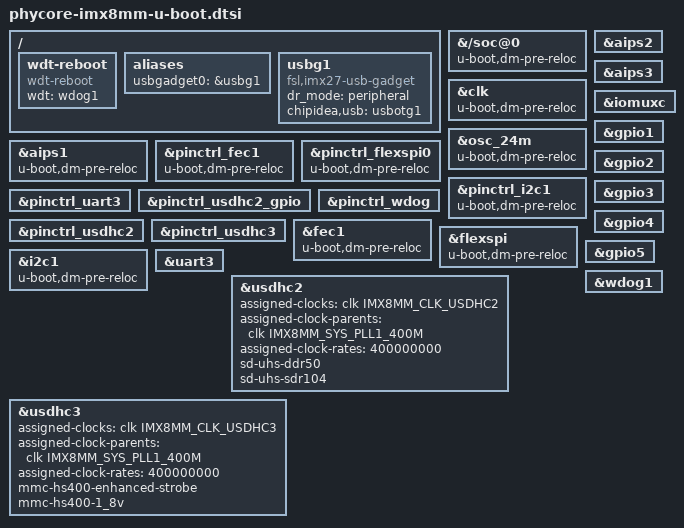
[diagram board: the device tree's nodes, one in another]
// SPDX-License-Identifier: GPL-2.0-or-later
/*
 * Copyright (C) 2020 PHYTEC Messtechnik GmbH
 * Author: Teresa Remmet <t.remmet@phytec.de>
 */

/ {
	wdt-reboot {
		compatible = "wdt-reboot";
		wdt = <&wdog1>;
		u-boot,dm-spl;
	};

	aliases {
		usbgadget0 = &usbg1;
	};

	usbg1: usbg1 {
		compatible = "fsl,imx27-usb-gadget";
		dr_mode = "peripheral";
		chipidea,usb = <&usbotg1>;
		status = "okay";
	};
};

&{/soc@0} {
	u-boot,dm-pre-reloc;
	u-boot,dm-spl;
};

&clk {
	u-boot,dm-spl;
	u-boot,dm-pre-reloc;
	/delete-property/ assigned-clocks;
	/delete-property/ assigned-clock-parents;
	/delete-property/ assigned-clock-rates;
};

&osc_24m {
	u-boot,dm-spl;
	u-boot,dm-pre-reloc;
};

&aips1 {
	u-boot,dm-spl;
	u-boot,dm-pre-reloc;
};

&aips2 {
	u-boot,dm-spl;
};

&aips3 {
	u-boot,dm-spl;
};

&iomuxc {
	u-boot,dm-spl;
};

&pinctrl_fec1 {
	u-boot,dm-pre-reloc;
};

&pinctrl_flexspi0 {
	u-boot,dm-pre-reloc;
};

&pinctrl_i2c1 {
	u-boot,dm-spl;
	u-boot,dm-pre-reloc;
};

&pinctrl_uart3 {
	u-boot,dm-spl;
};

&pinctrl_usdhc2_gpio {
	u-boot,dm-spl;
};

&pinctrl_usdhc2 {
	u-boot,dm-spl;
};

&pinctrl_usdhc3 {
	u-boot,dm-spl;
};

&pinctrl_wdog {
	u-boot,dm-spl;
};

&fec1 {
	u-boot,dm-pre-reloc;
};

&flexspi {
	u-boot,dm-pre-reloc;
};

&gpio1 {
	u-boot,dm-spl;
};

&gpio2 {
	u-boot,dm-spl;
};

&gpio3 {
	u-boot,dm-spl;
};

&gpio4 {
	u-boot,dm-spl;
};

&gpio5 {
	u-boot,dm-spl;
};

&i2c1 {
	u-boot,dm-spl;
	u-boot,dm-pre-reloc;
};

&uart3 {
	u-boot,dm-spl;
};

&usdhc2 {
	assigned-clocks = <&clk IMX8MM_CLK_USDHC2>;
	assigned-clock-parents = <&clk IMX8MM_SYS_PLL1_400M>;
	assigned-clock-rates = <400000000>;
	sd-uhs-ddr50;
	sd-uhs-sdr104;
	u-boot,dm-spl;
};

&usdhc3 {
	assigned-clocks = <&clk IMX8MM_CLK_USDHC3>;
	assigned-clock-parents = <&clk IMX8MM_SYS_PLL1_400M>;
	assigned-clock-rates = <400000000>;
	mmc-hs400-enhanced-strobe;
	mmc-hs400-1_8v;
	u-boot,dm-spl;
};

&wdog1 {
	u-boot,dm-spl;
};
